# i2c_slave_model: IP-XACT component
VLNV IcronTechnologies:IcronTechnologies:i2c_slave_model:1.0

## Parameters
addr_width = 8
bus_width = 32

## Bus interfaces (logical=physical port)
default_map: slave AGNISYS:AGNISYS:APB:1.0, memory map i2c_slavemap
  pclk=pclk, presetn=presetn, psel=psel, penable=penable, pwrite=pwrite, pprot=pprot, pstrb=pstrb, pwdata=pwdata, paddr=paddr, pready=pready, prdata=prdata, pslverr=pslverr

## Ports
in pclk
in presetn
in psel
in penable
in pwrite
in pprot[2:0]
in pstrb[(bus_width div 8 )-1:0]
in pwdata[bus_width -1:0]
in paddr[addr_width -1:0]
out pready
out prdata[bus_width -1:0]
out pslverr
out i2c_slave_regsversion_major_r[7:0]
out i2c_slave_regsversion_minor_r[7:0]
out i2c_slave_regsversion_patch_r[7:0]
out i2c_slave_regsin_fifo_enb
out i2c_slave_regsin_fifo_fifo_clear_r
out i2c_slave_regsregin_fifo_fifo_clear_wr_pulse
in i2c_slave_regsin_fifo_fifo_af_in
in i2c_slave_regsin_fifo_fifo_af_in_enb
in i2c_slave_regsin_fifo_fifo_ae_in
in i2c_slave_regsin_fifo_fifo_ae_in_enb
in i2c_slave_regsin_fifo_fifo_full_in
in i2c_slave_regsin_fifo_fifo_full_in_enb
in i2c_slave_regsin_fifo_fifo_empty_in
in i2c_slave_regsin_fifo_fifo_empty_in_enb
out i2c_slave_regsin_fifo_fifo_aft_r[7:0]
out i2c_slave_regsin_fifo_fifo_aet_r[7:0]
in i2c_slave_regsin_fifo_fifo_depth_in[7:0]
in i2c_slave_regsin_fifo_fifo_depth_in_enb
out i2c_slave_regsout_fifo_enb
out i2c_slave_regsout_fifo_fifo_clear_r
out i2c_slave_regsregout_fifo_fifo_clear_wr_pulse
in i2c_slave_regsout_fifo_fifo_af_in
in i2c_slave_regsout_fifo_fifo_af_in_enb
in i2c_slave_regsout_fifo_fifo_ae_in
in i2c_slave_regsout_fifo_fifo_ae_in_enb
in i2c_slave_regsout_fifo_fifo_full_in
in i2c_slave_regsout_fifo_fifo_full_in_enb
in i2c_slave_regsout_fifo_fifo_empty_in
in i2c_slave_regsout_fifo_fifo_empty_in_enb
out i2c_slave_regsout_fifo_fifo_aft_r[7:0]
out i2c_slave_regsout_fifo_fifo_aet_r[7:0]
in i2c_slave_regsout_fifo_fifo_depth_in[7:0]
in i2c_slave_regsout_fifo_fifo_depth_in_enb
out i2c_slave_regsslave_config_enb
out i2c_slave_regsslave_config_no_device_busy_r
out i2c_slave_regsslave_config_no_reply_data_rdy_r
out i2c_slave_regsslave_config_no_status_r
out i2c_slave_regsslave_config_stop_clks_r[3:0]
out i2c_slave_regsslave_config_start_clks_r[3:0]
out i2c_slave_regsslave_config_sda_glitch_r[3:0]
out i2c_slave_regsslave_config_scl_glitch_r[3:0]
out i2c_slave_regsslave_config_clock_stretch_en_r
out i2c_slave_regsslave_config_slave_addr_ack_r
out i2c_slave_regsslave_config_slave_addr_r[6:0]
out i2c_slave_regstimeout_enb
out i2c_slave_regstimeout_val_r[31:0]
out i2c_slave_regsstatus_enb
in i2c_slave_regsstatus_device_busy_in
in i2c_slave_regsstatus_device_busy_in_enb
out i2c_slave_regsstatus_device_busy_r
out i2c_slave_regsstatus_req_nak_r
out i2c_slave_regsstatus_rsvd5_r
out i2c_slave_regsstatus_rsvd4_r
out i2c_slave_regsstatus_reply_data_rdy_r
in i2c_slave_regsstatus_reply_data_rdy_hw_clear
out i2c_slave_regsstatus_reply_req_r
out i2c_slave_regsstatus_rsvd1_r
out i2c_slave_regsstatus_rsvd0_r
out i2c_slave_regswr_data_enb
out i2c_slave_regswr_data_wr_data_r[7:0]
out i2c_slave_regsregwr_data_wr_data_wr_pulse
in i2c_slave_regsrd_data_rd_data_in[7:0]
in i2c_slave_regsrd_data_rd_data_in_enb
out i2c_slave_regsrd_data_rd_data_rd_pulse

## Address spaces and blocks
i2c_slavemap.i2c_slave: base 0x000, range 0x100, width 32

## Registers
Registers are 32-bit, read-write, reset 0x0 unless marked. A register's access mark holds for its fields unless they carry their own. Offsets are from the block's base; lines under a group give offsets from that group; [hi:lo] are bit positions; {n}, {i} and the like mark numbered series; 'fields as' and 'values as' point back to an identical list; <NAME> marks a mode.

## i2c_slavemap.i2c_slave — I2C Slave
Base 0x00000000
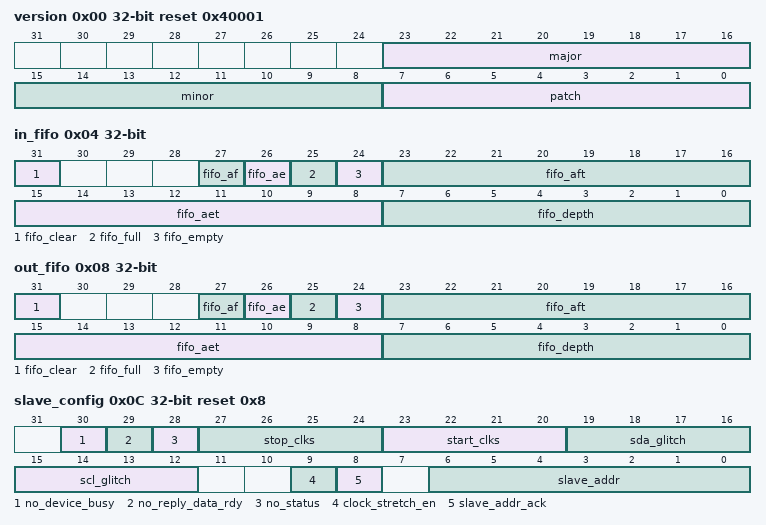
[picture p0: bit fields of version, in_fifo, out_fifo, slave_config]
0x00 version ro reset 0x40001
  [23:16] major — Major version
  [15:8] minor — Minor version
  [7:0] patch — Patch version
0x04 in_fifo access per field — Input FIFO control and status
  [31] fifo_clear rw
  [27] fifo_af ro — FIFO almost full status field. A 1 indicates an almost full or full FIFO. This bit is set when there are between fifo_aft and fifo_depth number of entries in the FIFO.
  [26] fifo_ae ro — FIFO almost empty status field. A 1 indicates an almost empty or empty FIFO. This bit is set when there are between 0 and fifo_aet number of entries in the FIFO.
  [25] fifo_full ro — FIFO full status field. A 1 indicates a full FIFO.
  [24] fifo_empty ro — FIFO empty status field. A 1 indicates an empty FIFO.
  [23:16] fifo_aft rw — FIFO almost full threshold
  [15:8] fifo_aet rw — FIFO almost empty threshold
  [7:0] fifo_depth ro — FIFO depth (always 1 byte wide)
0x08 out_fifo access per field — Output FIFO control and status
  fields as in_fifo
0x0C slave_config reset 0x8 — Config
  [30] no_device_busy — Prevent HW setting device_busy
  [29] no_reply_data_rdy — Prevent HW clearing the reply_data_rdy
  [28] no_status — Do not send the status byte
  [27:24] stop_clks — Declare a start (P) if there were at least stop_clks + 2 clock cycles between the SCL rising edge and the SDA rising edge
  [23:20] start_clks — Declare a start (S) if there were at least start_clks + 2 clock cycles between the SDA falling edge and the SCL falling edge
  [19:16] sda_glitch — Filter glitches up to this number + 1 clock cycles on the SDA line
  [15:12] scl_glitch — Filter glitches up to this number + 1 clock cycles on the SCL line
  [9] clock_stretch_en — Enable clock stretching - Active High
  [8] slave_addr_ack — Slave address ACK - Active High
  [6:0] slave_addr — Slave address
0x10 timeout
  [31:0] val — Timeout value in number of clock cycles (SMBus) A value of 0x0 disables the timeout (I2C)
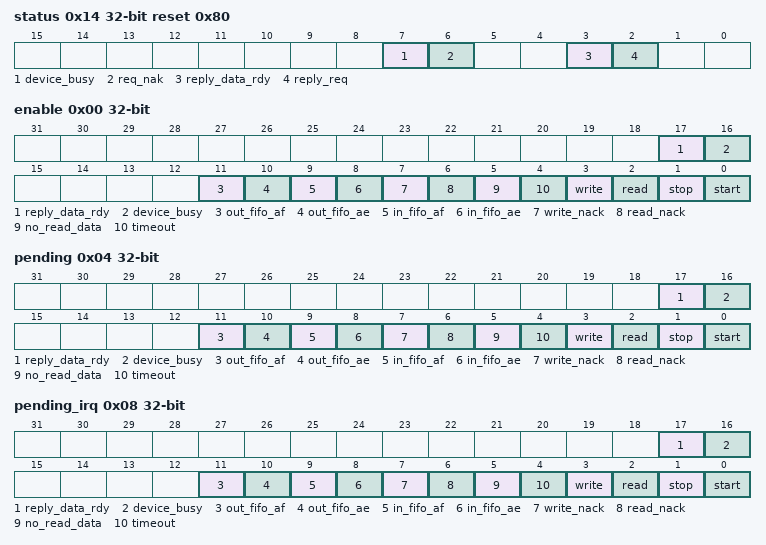
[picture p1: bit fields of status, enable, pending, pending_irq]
0x14 status reset 0x80
  [7] device_busy — Device Busy - set by the hardware at the end of a transaction by the Master that writes to the request data area. Cleared by the slave CPU when it has read the data and responded to the command.
  [6] req_nak — Request NAK - set by the slave if a request could not be filled; the reply data will need to be read before the hardware will clear this bit (same as Reply Data Ready)
  [3] reply_data_rdy — Reply Data Ready - set by SW when data is ready for the master; cleared by HW when the output FIFO is empty
  [2] reply_req — Reply Request - indicates the type of data the slave has for the master. If set, the data is a reply to a previous request from the master. If cleared, this is unsolicited status information the slave has for the master
0x18 wr_data wo — Write data
  [7:0] wr_data — Byte to write into the output FIFO.
0x1C rd_data ro — Read data
  [7:0] rd_data — Byte to read from the input FIFO.
0x20 irq group — Interrupt register group
  0x00 enable — Interrupt Enable register - Write 1 to enable, 0 to mask an interrupt
    [17] reply_data_rdy — Reply data ready
    [16] device_busy
    [11] out_fifo_af — Output FIFO almost full
    [10] out_fifo_ae — Output FIFO almost empty NOTE: If the FIFO is empty when this interrupt is enabled, it will cause an interrupt right away!
    [9] in_fifo_af — Input FIFO almost full
    [8] in_fifo_ae — Input FIFO almost empty NOTE: If the FIFO is empty when this interrupt is enabled, it will cause an interrupt right away!
    [7] write_nack — Write data was NACK-ed by the slave
    [6] read_nack — Read data was NACK-ed by the master
    [5] no_read_data — Read data is requested but there is no data to provide (slave is clock stretching if enabled or else returning all 1s)
    [4] timeout — SCL was low for timeout.val module clock cycles
    [3] write — The bit after an acknowledged slave address indicates a write operation
    [2] read — The bit after an acknowledged slave address indicates a read operation
    [1] stop — Stop bit detected
    [0] start — Start or Repeated Start bit detected
  0x04 pending — Pending register - This indicates which events are pending, Write 1 to clear
    [17] reply_data_rdy write-1-clears — Edge-triggered - Active-High Reply data ready
    [16] device_busy write-1-clears — Edge-triggered - Active-High Device busy
    [11] out_fifo_af write-1-clears — Level-triggered - Active-High Output FIFO almost full
    [10] out_fifo_ae write-1-clears — Level-triggered - Active High Output FIFO almost empty NOTE: If the FIFO is empty, this event is pending and if enabled will cause an interrupt!
    [9] in_fifo_af write-1-clears — Level-triggered - Active-High Input FIFO almost full
    [8] in_fifo_ae write-1-clears — Level-triggered - Active High Input FIFO almost empty NOTE: If the FIFO is empty, this event is pending and if enabled will cause an interrupt!
    [7] write_nack write-1-clears — Edge-triggered - Active-High Write NACK
    [6] read_nack write-1-clears — Edge-triggered - Active-High Read NACK
    [5] no_read_data write-1-clears — Edge-triggered - Active-High No Read Data
    [4] timeout write-1-clears — Edge-triggered - Active-High Timeout
    [3] write write-1-clears — Edge-triggered - Active-High Write
    [2] read write-1-clears — Edge-triggered - Active-High Read
    [1] stop write-1-clears — Edge-triggered - Active-High Stop
    [0] start write-1-clears — Edge-triggered - Active-High Start
  0x08 pending_irq ro — Interrupt Pending register - This indicates which pending events are enabled to cause an interrupt
    [17] reply_data_rdy — Edge-triggered - Active-High Reply data ready
    [16] device_busy — Edge-triggered - Active-High Device busy
    [11] out_fifo_af — Level-triggered - Active-High Output FIFO almost full
    [10] out_fifo_ae — Level-triggered - Active High Output FIFO almost empty
    [9] in_fifo_af — Level-triggered - Active-High Input FIFO almost full
    [8] in_fifo_ae — Level-triggered - Active High Input FIFO almost empty
    [7] write_nack — Edge-triggered - Active-High Write NACK
    [6] read_nack — Edge-triggered - Active-High Read NACK
    [5] no_read_data — Edge-triggered - Active-High No Read Data
    [4] timeout — Edge-triggered - Active-High Timeout
    [3] write — Edge-triggered - Active-High Write
    [2] read — Edge-triggered - Active-High Read
    [1] stop — Edge-triggered - Active-High Stop
    [0] start — Edge-triggered - Active-High Start
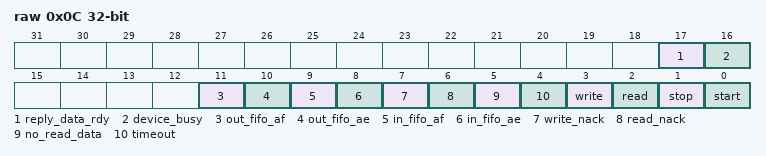
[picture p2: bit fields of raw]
  0x0C raw ro — This register contains the registered state of interrupt signals
    [17] reply_data_rdy — Current state of the reply data ready flag (Active-High)
    [16] device_busy — Current state of the device busy flag (Active-High)
    [11] out_fifo_af — Current state of the output FIFO almost full flag (Active-High)
    [10] out_fifo_ae — Current state of the output FIFO almost empty flag (Active-High)
    [9] in_fifo_af — Current state of the input FIFO almost full flag (Active-High)
    [8] in_fifo_ae — Current state of the input FIFO almost empty flag (Active-High)
    [7] write_nack — Current state of the write nack flag (Active-High)
    [6] read_nack — Current state of the read nack flag (Active-High)
    [5] no_read_data — Current state of the no read data flag (Active-High)
    [4] timeout — Current state of the timeout flag (Active-High)
    [3] write — Current state of the write flag (Active-High)
    [2] read — Current state of the read flag (Active-High)
    [1] stop — Current state of the stop flag (Active-High)
    [0] start — Current state of the start flag (Active-High)
